# STM32F730 register map
File version: 1.5
CPU: CM7 r0p1, little endian, MPU, FPU, 4 interrupt priority bits
Registers are 32-bit, read-write, reset 0x0 unless marked. A register's access mark holds for its fields unless they carry their own. Offsets are from the block's base; [hi:lo] are bit positions; {n}, {i} and the like mark numbered series.

## OTG_HS_PWRCLK — USB on the go high speed
Base 0x40040E00
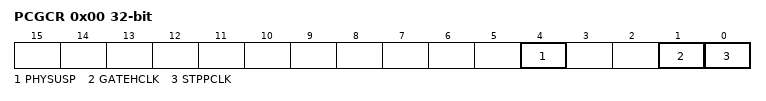
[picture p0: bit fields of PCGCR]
0x00 PCGCR — Power and clock gating control register
  [4] PHYSUSP — PHY suspended
  [1] GATEHCLK
  [0] STPPCLK — Stop PHY clock

## WWDG — Window watchdog
Base 0x40002C00
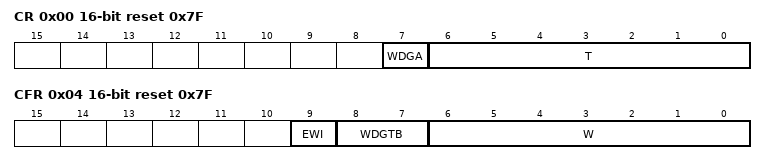
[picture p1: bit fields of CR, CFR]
0x00 CR 16-bit reset 0x7F — Control register
  [7] WDGA — Activation bit
    0=Disabled (Watchdog disabled); 1=Enabled (Watchdog enabled)
  [6:0] T — 7-bit counter (MSB to LSB)
0x04 CFR 16-bit reset 0x7F — Configuration register
  [9] EWI — Early wakeup interrupt
    on write: 1=Enable (interrupt occurs whenever the counter reaches the value 0x40)
  [8:7] WDGTB — Timer base
    0=Div1 (Counter clock (PCLK1 div 4096) div 1); 1=Div2 (Counter clock (PCLK1 div 4096) div 2); 2=Div4 (Counter clock (PCLK1 div 4096) div 4); 3=Div8 (Counter clock (PCLK1 div 4096) div 8)
  [6:0] W — 7-bit window value
0x08 SR 16-bit — Status register
  [0] EWIF write-0-clears — Early wakeup interrupt flag
    on read: 0=Finished (The EWI Interrupt Service Routine has been serviced); 1=Pending (The EWI Interrupt Service Routine has been triggered) | on write: 0=Finished (The EWI Interrupt Service Routine has been serviced)

## AES — Advanced encryption standard hardware accelerator 1
Base 0x50060000
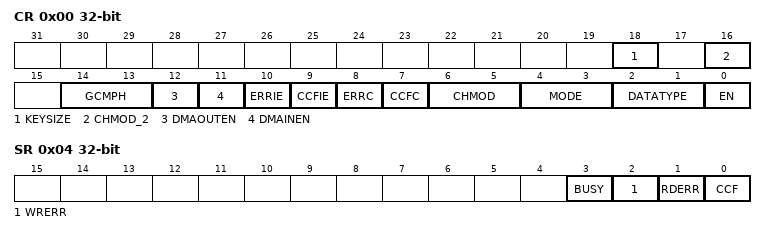
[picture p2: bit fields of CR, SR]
0x00 CR — control register
  [18] KEYSIZE — Key size selection
    0=AES128 (128); 1=AES256 (256)
  [16] CHMOD_2 — AES chaining mode Bit2
    0=CHMOD (Mode as per CHMOD (ECB, CBC, CTR, GCM)); 1=CCM (Counter with CBC-MAC (CCM) - CHMOD must be 0 (ECB))
  [14:13] GCMPH — Used only for GCM, CCM and GMAC algorithms and has no effect when other algorithms are selected
    0=Init phase; 1=Header phase; 2=Payload phase; 3=Final Phase
  [12] DMAOUTEN — Enable DMA management of data output phase
    0=Disable DMA Output; 1=Enabled DMA Output
  [11] DMAINEN — Enable DMA management of data input phase
    0=Disable DMA Input; 1=Enable DMA Input
  [10] ERRIE — Error interrupt enable
    0=Disabled (Disable (mask) error interrupt); 1=Enabled (Enable error interrupt)
  [9] CCFIE — CCF flag interrupt enable
    0=Disabled (Disable (mask) CCF interrupt); 1=Enabled (Enable CCF interrupt)
  [8] ERRC — Error clear
    on write: 1=Clear RDERR and WRERR flags
  [7] CCFC — Computation Complete Flag Clear
    on write: 1=Clear computation complete flag
  [6:5] CHMOD — AES chaining mode Bit1 Bit0
    0=ECB (Electronic codebook (ECB) / Counter with CBC-MAC (CCM) if CHMOD2 is 1); 1=CBC (Cipher-block chaining (CBC)); 2=CTR (Counter mode (CTR)); 3=GCM (Galois counter mode (GCM) and Galois message authentication code (GMAC))
  [4:3] MODE — AES operating mode
    0=Mode 1: encryption; 1=Mode 2: key derivation (or key preparation for ECB/CBC decryption); 2=Mode 3: decryption; 3=Mode 4: key derivation then single decryption
  [2:1] DATATYPE — Data type selection (for data in and data out to/from the cryptographic block)
    0=None (Word); 1=Half-word (16-bit); 2=Byte (8-bit); 3=Bit
  [0] EN — AES enable
    0=Disabled (Disable AES); 1=Enabled (Enable AES)
0x04 SR ro — status register
  [3] BUSY — Busy flag
    0=Idle; 1=Busy
  [2] WRERR — Write error flag
    0=NoError (Write error not detected); 1=Error (Write error detected)
  [1] RDERR — Read error flag
    0=NoError (Read error not detected); 1=Error (Read error detected)
  [0] CCF — Computation complete flag
    0=Complete (Computation complete); 1=NotComplete (Computation not complete)
0x08 DINR — data input register
  [31:0] DIN — Data Input Register
0x0C DOUTR ro — data output register
  [31:0] DOUT — Data output register
0x10 KEYR0 — key register 0
  [31:0] KEY — Data Output Register (LSB key [31:0])
0x14 KEYR1 — key register 1
  [31:0] KEY — AES key register (key [63:32])
0x18 KEYR2 — key register 2
  [31:0] KEY — AES key register (key [95:64])
0x1C KEYR3 — key register 3
  [31:0] KEY — AES key register (MSB key [127:96])
0x20 IVR0 — initialization vector register 0
  [31:0] IVI — initialization vector register (LSB IVR [31:0])
0x24 IVR1 — initialization vector register 1
  [31:0] IVI — Initialization Vector Register (IVR [63:32])
0x28 IVR2 — initialization vector register 2
  [31:0] IVI — Initialization Vector Register (IVR [95:64])
0x2C IVR3 — initialization vector register 3
  [31:0] IVI — Initialization Vector Register (MSB IVR [127:96])
{0x20+4i} KEYR{i} (i=4..7) — key register {i}
  [31:0] KEY — AES key register (MSB key [{32i+31}:{32i}])
{0x40+4i} SUSP{i}R (i=0..7) — AES suspend register {i}
  [31:0] SUSP

## USBPHYC — USBPHYC register interface
Base 0x40017C00
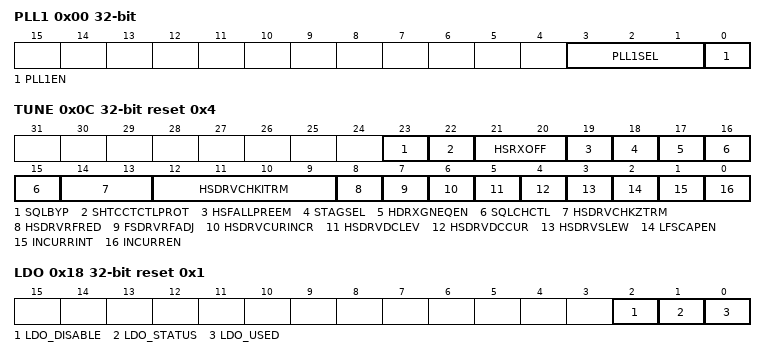
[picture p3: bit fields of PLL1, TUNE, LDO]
0x00 PLL1 — USBPHYC PLL1 control register
  [3:1] PLL1SEL — : Controls the PHY PLL1 input clock frequency selection
  [0] PLL1EN — Enable the PLL1 inside PHY
0x0C TUNE reset 0x4 — USBPHYC tuning control register
  [23] SQLBYP — This pin is used to bypass the squelch inter-locking circuitry
  [22] SHTCCTCTLPROT — Enables the short circuit protection circuitry in LS/FS driver
  [21:20] HSRXOFF — : HS Receiver Offset adjustment
  [19] HSFALLPREEM — HS Fall time control of single ended signals during pre-emphasis
  [18] STAGSEL — HS Tx staggering enable
  [17] HDRXGNEQEN — Enables the HS Rx Gain Equalizer
  [16:15] SQLCHCTL — Adjust the squelch DC threshold value
  [14:13] HSDRVCHKZTRM — Controls the PHY bus HS driver impedance tuning for choke compensation
  [12:9] HSDRVCHKITRM — HS Driver current trimming pins for choke compensation
  [8] HSDRVRFRED — High Speed rise-fall reduction enable
  [7] FSDRVRFADJ — Tuning pin to adjust the full speed rise/fall time
  [6] HSDRVCURINCR — Enable the HS driver current increase feature
  [5] HSDRVDCLEV — Increases the HS Driver DC level. Not applicable during the HS Test J and Test K data transfer
  [4] HSDRVDCCUR — Decreases the HS driver DC level
  [3] HSDRVSLEW — Controls the HS driver slew rate
  [2] LFSCAPEN — : Enables the Low Full Speed feedback capacitor
  [1] INCURRINT — Controls PHY current boosting
  [0] INCURREN — Controls the current boosting function
0x18 LDO access per field reset 0x1 — USBPHYC LDO control and status register
  [2] LDO_DISABLE rw — Controls disable of the High Speed PHY's LDO
  [1] LDO_STATUS ro — Monitors the status of the PHY's LDO
  [0] LDO_USED ro — Indicates the presence of the LDO in the chip
